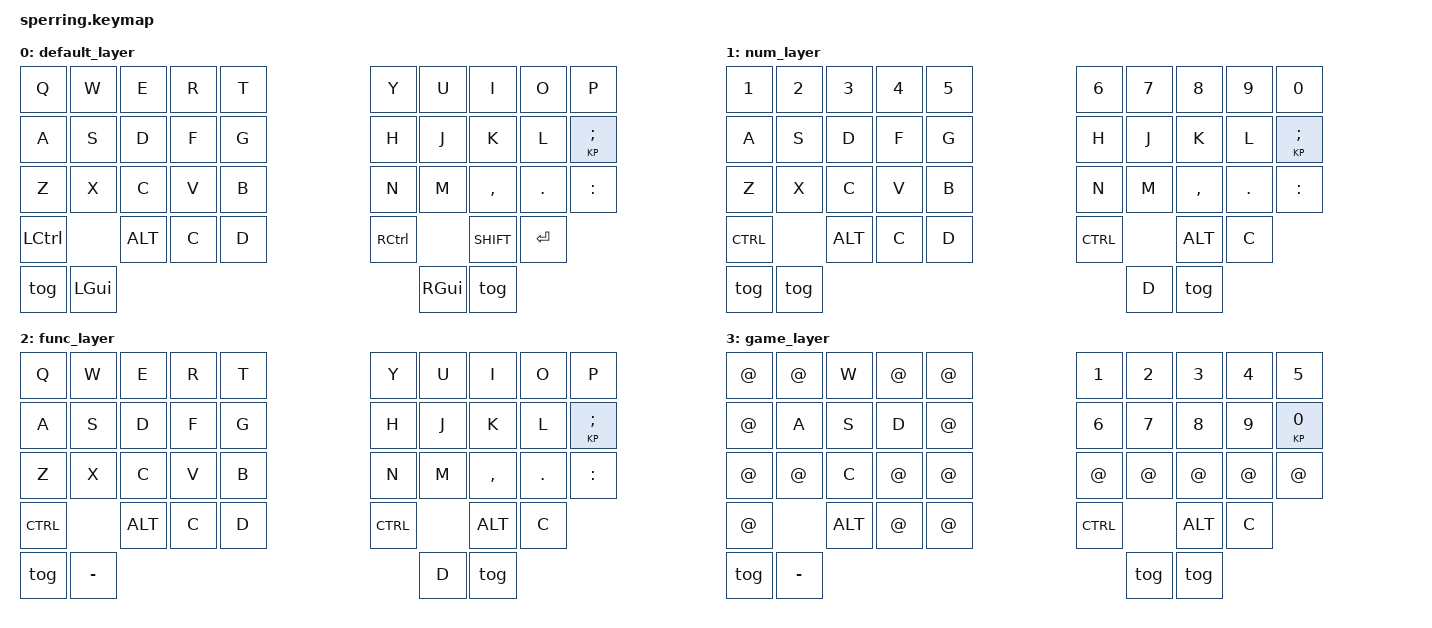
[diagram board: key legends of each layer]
// This file was generated from a template. Edit it to match your keyboard.
// See https://zmk.dev/docs/development/hardware-integration/new-shield for more instructions.

#include <behaviors.dtsi>
#include <dt-bindings/zmk/keys.h>

/ {
    // Define a default keymap here.
    // See https://zmk.dev/docs/development/hardware-integration/new-shield#default-keymap.
    keymap {
        compatible = "zmk,keymap";

        default_layer {
          display_name = "default layer";
          // ------------------------------------------------------------------------------------------------------------
          // |  Q  |  W  |  E   |  R   |  T   |                   |  Y   |  U    |  I    |  O   |   P |
          // |  A  |  S  |  D   |  F   |  G   |                   |  H   |  J    |  K    |  L   | ;   |
          // |  Z  |  X  |  C   |  V   |  B   |                   |  N   |  M    |  ,    |  .   | :   |
          // |  CTRL  |  ALT  |  SPACE   |                        |  SPACE   |  ESC   |  ENTER   |
          // |  L1  |    |                                        |  SPACE   |  l2   |
            bindings = <
                &kp Q &kp W &kp E &kp R &kp T                     &kp Y &kp U &kp I      &kp O   &kp P
                &kp A &kp S &kp D &kp F &kp G                     &kp H &kp J &kp K      &kp L   &KP SEMI
                &kp Z &kp X &kp C &kp V &kp B                     &kp N &kp M &kp COMMA  &kp DOT &kp COLON
                &kp LCTRL &kp ALT &kp C  &kp D                    &kp RCTRL &kp SHIFT &kp RET 
                &kp tog 1   &kp LGUI                              &kp RGUI   &kp tog 2                
            >;
        };
        num_layer {
          display_name = "num layer";
          // ------------------------------------------------------------------------------------------------------------
          // |  1  |  2  |  3   |  4   |  5   |                   |  6   |  7    |  8    |  9   |  0  |
          // |  A  |  S  |  D   |  F   |  G   |                   |  H   |  J    |  K    |  L   |  ;  |
          // |  Z  |  X  |  C   |  V   |  B   |                   |  N   |  M    |  ,    |  .   |  :  |
          // |  CTRL  |  ALT  |  SPACE   |                        |  SPACE   |  ESC   |  RET   |
          // |  L1  |   R|                                        |  SPACE   |  l2   |
            bindings = <
                &kp N1 &kp N2 &kp N3 &kp N4 &kp N5                &kp N6 &kp N7 &kp N8 &kp N9   &kp N0
                &kp A &kp S &kp D &kp F &kp G                     &kp H &kp J &kp K      &kp L   &KP SEMI
                &kp Z &kp X &kp C &kp V &kp B                     &kp N &kp M &kp COMMA  &kp DOT &kp COLON
                &kp CTRL &kp ALT &kp C  &kp D                     &kp CTRL &kp ALT &kp C 
                 &kp tog 0   &kp tog 3                                &kp D   &kp tog 2                
            >;
        };
        func_layer {
          display_name = "func layer";
          // ------------------------------------------------------------------------------------------------------------
          // |  1  |  W  |  E   |  R   |  T   |                   |  Y   |  U    |  I    |  O   |   P |
          // |  A  |  S  |  D   |  F   |  G   |                   |  H   |  J    |  K    |  L   | ;   |
          // |  Z  |  X  |  C   |  V   |  B   |                   |  N   |  M    |  ,    |  .   | :   |
          // |  CTRL  |  ALT  |  SPACE   |                        |  SPACE   |  ESC   |  RET   |
          // |  L1  |    |                                        |  SPACE   |  l2   |
            bindings = <
                &kp Q &kp W &kp E &kp R &kp T                     &kp Y &kp U &kp I      &kp O   &kp P
                &kp A &kp S &kp D &kp F &kp G                     &kp H &kp J &kp K      &kp L   &KP SEMI
                &kp Z &kp X &kp C &kp V &kp B                     &kp N &kp M &kp COMMA  &kp DOT &kp COLON
                &kp CTRL &kp ALT &kp C  &kp D                     &kp CTRL &kp ALT &kp C 
                 &kp tog 0   &kp MINUS                                &kp D   &kp tog 1                
            >;
        };
        game_layer {
          display_name = "game layer";
          // ------------------------------------------------------------------------------------------------------------
          // |     |     |  W   |      |      |                   |  1   |  2    |  3    |  4   |   5 |
          // |     |  A  |  S   |  D   |      |                   |  6   |  7   |  8    |  9   | 0   |
          // |     |     |      |      |      |                   |  N   |  M    |  ,    |  .   | :   |
          // |     |     |     |                                  |      |       |       |
          // |  L0  |    |                                        |  SPACE   |  l1   |
            bindings = <
                &kp AT &kp AT &kp W &kp AT &kp AT                   &kp N1   &kp N2  &kp N3      &kp N4   &kp N5
                &kp AT &kp A &kp S &kp D &kp AT                     &kp N6   &kp N7  &kp N8      &kp N9   &KP N0
                &kp AT &kp AT &kp C &kp AT &kp AT                   &kp AT   &kp AT  &kp AT      &kp AT &kp AT
                &kp AT &kp ALT &kp AT  &kp AT                       &kp CTRL &kp ALT &kp C 
                 &kp tog 0   &kp MINUS                              &kp tog 2   &kp tog 1                
            >;
        };
    };
};
